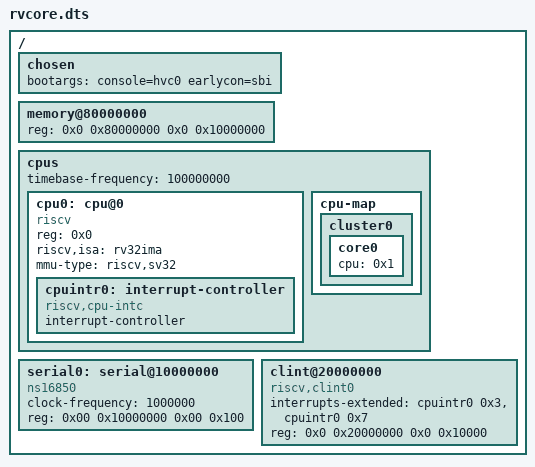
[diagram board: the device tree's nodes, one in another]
/dts-v1/;
/ {
  #address-cells = <0x2>;
  #size-cells = <0x2>;

  chosen {
    bootargs = "console=hvc0 earlycon=sbi";
  };

  memory@80000000 {
    device_type = "memory";
    reg = <0x0 0x80000000 0x0 0x10000000>;
  };

  cpus {
    #address-cells = <0x1>;
    #size-cells = <0x0>;
    timebase-frequency = <100000000>;
    cpu0: cpu@0 {
      phandle = <0x1>;
      device_type = "cpu";
      reg = <0x0>;
      status = "okay";
      compatible = "riscv";
      riscv,isa = "rv32ima";
      mmu-type = "riscv,sv32";
      cpuintr0: interrupt-controller {
        #interrupt-cells = <0x1>;
        interrupt-controller;
        compatible = "riscv,cpu-intc";
        phandle = <0x2>;
      };
    };
    cpu-map {
      cluster0 {
        core0 {
          cpu = <0x1>;
        };
      };
    };
  };

  serial0: serial@10000000 {
    clock-frequency = <1000000>;
    reg = <0x00 0x10000000 0x00 0x100>;
    compatible = "ns16850";
  };

  clint@20000000 {
    interrupts-extended = <&cpuintr0 0x3 &cpuintr0 0x7>;
    reg = <0x0 0x20000000 0x0 0x10000>;
    compatible = "riscv,clint0";
  };

};
